# N32H49X register map
Vendor: Nsingtech Ltd.; File version: 1.0
Registers are 32-bit, read-write, reset 0x0 unless marked. A register's access mark holds for its fields unless they carry their own. Offsets are from the block's base; [hi:lo] are bit positions; {n}, {i} and the like mark numbered series; 'fields as' and 'values as' point back to an identical list.

## DVP — Digital video port
Base 0x40008400
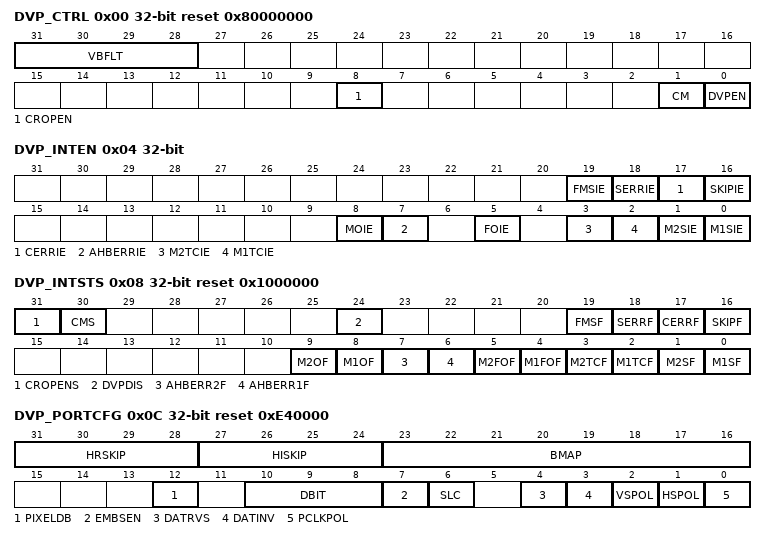
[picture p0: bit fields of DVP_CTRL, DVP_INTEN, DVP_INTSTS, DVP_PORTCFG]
0x00 DVP_CTRL reset 0x80000000
  [31:28] VBFLT, [8] CROPEN, [1] CM, [0] DVPEN
0x04 DVP_INTEN
  [19] FMSIE, [18] SERRIE, [17] CERRIE, [16] SKIPIE, [8] MOIE, [7] AHBERRIE, [5] FOIE, [3] M2TCIE, [2] M1TCIE, [1] M2SIE, [0] M1SIE
0x08 DVP_INTSTS reset 0x1000000
  [31] CROPENS ro, [30] CMS ro, [24] DVPDIS, [19] FMSF, [18] SERRF, [17] CERRF, [16] SKIPF, [9] M2OF, [8] M1OF, [7] AHBERR2F, [6] AHBERR1F, [5] M2FOF, [4] M1FOF, [3] M2TCF, [2] M1TCF, [1] M2SF, [0] M1SF
0x0C DVP_PORTCFG reset 0xE40000
  [31:28] HRSKIP, [27:24] HISKIP, [23:16] BMAP, [12] PIXELDB, [10:8] DBIT, [7] EMBSEN, [6] SLC, [4] DATRVS, [3] DATINV, [2] VSPOL, [1] HSPOL, [0] PCLKPOL
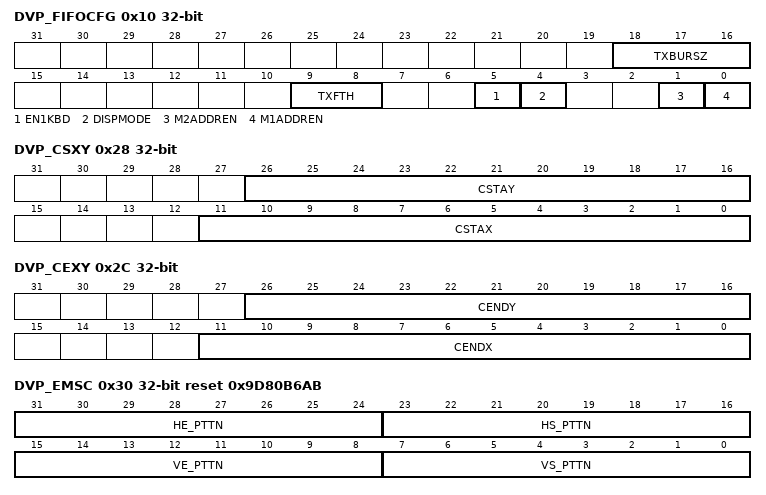
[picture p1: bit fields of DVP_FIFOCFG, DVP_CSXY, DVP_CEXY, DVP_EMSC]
0x10 DVP_FIFOCFG
  [18:16] TXBURSZ, [9:8] TXFTH, [5] EN1KBD, [4] DISPMODE, [1] M2ADDREN, [0] M1ADDREN
0x14 DVP_SMADDR1
  [31:0] MADDR
0x18 DVP_SMADDR2
  [31:0] MADDR
0x1C DVP_FBS
  [21:0] FMSIZE
0x20 DVP_FPBC1 ro
  [31:0] PIXLC
0x24 DVP_FPBC2 ro
  [31:0] PIXLC
0x28 DVP_CSXY
  [26:16] CSTAY, [11:0] CSTAX
0x2C DVP_CEXY
  [26:16] CENDY, [11:0] CENDX
0x30 DVP_EMSC reset 0x9D80B6AB
  [31:24] HE_PTTN, [23:16] HS_PTTN, [15:8] VE_PTTN, [7:0] VS_PTTN
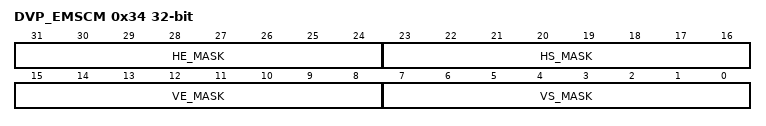
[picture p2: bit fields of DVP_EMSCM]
0x34 DVP_EMSCM
  [31:24] HE_MASK, [23:16] HS_MASK, [15:8] VE_MASK, [7:0] VS_MASK

## LPTIM1
Base 0x40006C00
Same registers: LPTIM2 0x40007000
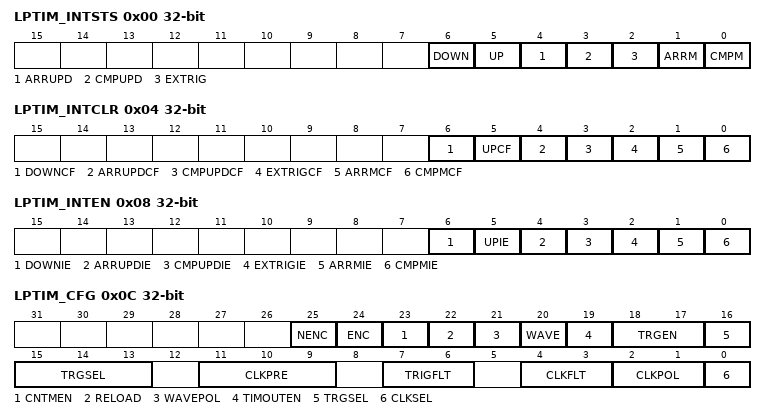
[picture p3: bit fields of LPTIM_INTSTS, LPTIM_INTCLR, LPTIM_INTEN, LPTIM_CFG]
0x00 LPTIM_INTSTS
  [6] DOWN, [5] UP, [4] ARRUPD, [3] CMPUPD, [2] EXTRIG, [1] ARRM, [0] CMPM
0x04 LPTIM_INTCLR
  [6] DOWNCF, [5] UPCF, [4] ARRUPDCF, [3] CMPUPDCF, [2] EXTRIGCF, [1] ARRMCF, [0] CMPMCF
0x08 LPTIM_INTEN
  [6] DOWNIE, [5] UPIE, [4] ARRUPDIE, [3] CMPUPDIE, [2] EXTRIGIE, [1] ARRMIE, [0] CMPMIE
0x0C LPTIM_CFG
  [25] NENC, [24] ENC, [23] CNTMEN, [22] RELOAD, [21] WAVEPOL, [20] WAVE, [19] TIMOUTEN, [18:17] TRGEN, [16:13] TRGSEL, [11:9] CLKPRE, [7:6] TRIGFLT, [4:3] CLKFLT, [2:1] CLKPOL, [0] CLKSEL
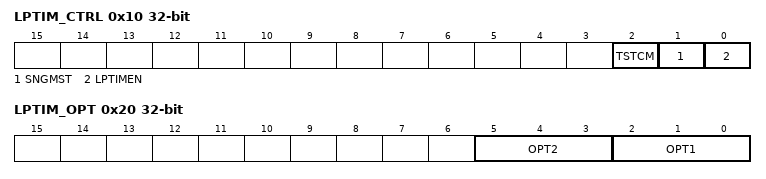
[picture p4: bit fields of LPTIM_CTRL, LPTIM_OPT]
0x10 LPTIM_CTRL
  [2] TSTCM, [1] SNGMST, [0] LPTIMEN
0x14 LPTIM_CMP
  [15:0] CMPVAL
0x18 LPTIM_ARR reset 0x1
  [15:0] ARRVAL
0x1C LPTIM_CNT
  [15:0] CNTVAL
0x20 LPTIM_OPT
  [5:3] OPT2, [2:0] OPT1

## USB_FS — Universal serial bus full-speed device interface
Base 0x40004800
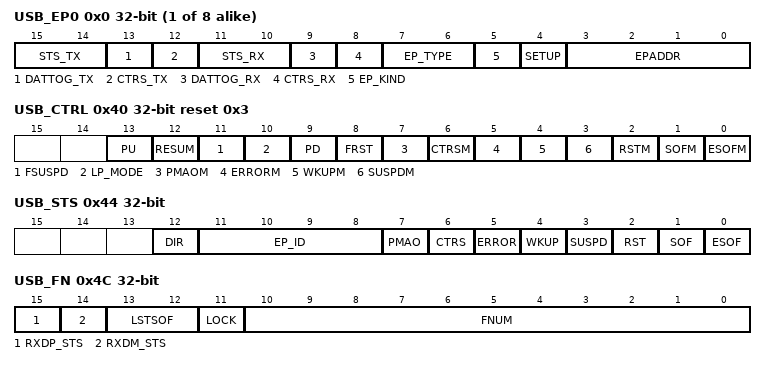
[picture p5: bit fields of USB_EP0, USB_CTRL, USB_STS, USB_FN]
{0x0+4i} USB_EP{i} (i=0..7)
  [15:14] STS_TX, [13] DATTOG_TX, [12] CTRS_TX, [11:10] STS_RX, [9] DATTOG_RX, [8] CTRS_RX, [7:6] EP_TYPE, [5] EP_KIND, [4] SETUP, [3:0] EPADDR
0x40 USB_CTRL reset 0x3 (reset mask 0xFF1F)
  [13] PU, [12] RESUM, [11] FSUSPD, [10] LP_MODE, [9] PD, [8] FRST, [7] PMAOM, [6] CTRSM, [5] ERRORM, [4] WKUPM, [3] SUSPDM, [2] RSTM, [1] SOFM, [0] ESOFM
0x44 USB_STS (reset mask 0xFF1F)
  [12] DIR, [11:8] EP_ID, [7] PMAO, [6] CTRS, [5] ERROR, [4] WKUP, [3] SUSPD, [2] RST, [1] SOF, [0] ESOF
0x48 USB_BUFTAB
  [15:3] BUFTAB
0x4C USB_FN
  [15] RXDP_STS, [14] RXDM_STS, [13:12] LSTSOF, [11] LOCK, [10:0] FNUM
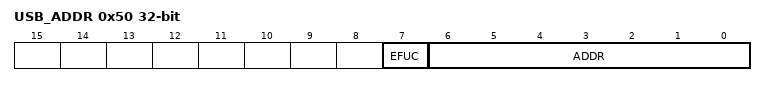
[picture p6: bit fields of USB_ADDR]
0x50 USB_ADDR (reset mask 0x7F)
  [7] EFUC, [6:0] ADDR

## USB_HS — USB high speed dual role
Base 0x40040000
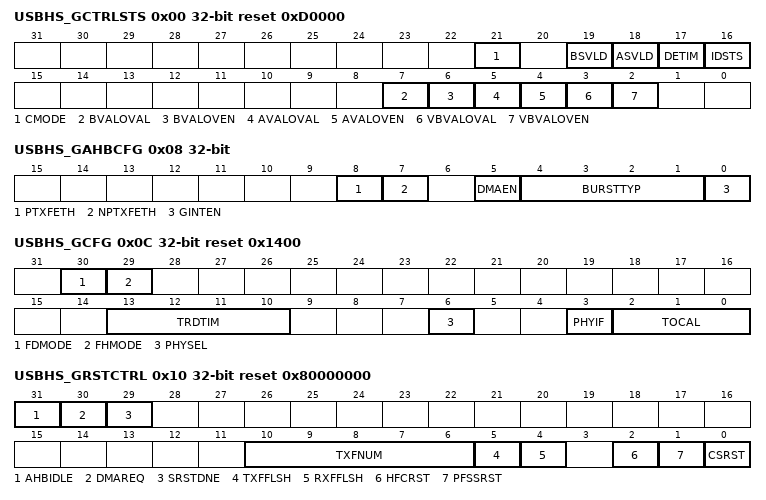
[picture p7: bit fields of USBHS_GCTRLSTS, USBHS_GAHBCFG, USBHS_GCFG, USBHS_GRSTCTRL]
0x00 USBHS_GCTRLSTS reset 0xD0000 — USBHS global control and status register
  [21] CMODE ro, [19] BSVLD ro, [18] ASVLD ro, [17] DETIM ro, [16] IDSTS ro, [7] BVALOVAL, [6] BVALOVEN, [5] AVALOVAL, [4] AVALOVEN, [3] VBVALOVAL, [2] VBVALOVEN
0x08 USBHS_GAHBCFG
  [8] PTXFETH, [7] NPTXFETH, [5] DMAEN, [4:1] BURSTTYP, [0] GINTEN
0x0C USBHS_GCFG reset 0x1400
  [30] FDMODE, [29] FHMODE, [13:10] TRDTIM, [6] PHYSEL, [3] PHYIF wo, [2:0] TOCAL
0x10 USBHS_GRSTCTRL reset 0x80000000
  [31] AHBIDLE ro, [30] DMAREQ ro, [29] SRSTDNE ro, [10:6] TXFNUM, [5] TXFFLSH, [4] RXFFLSH, [2] HFCRST, [1] PFSSRST, [0] CSRST
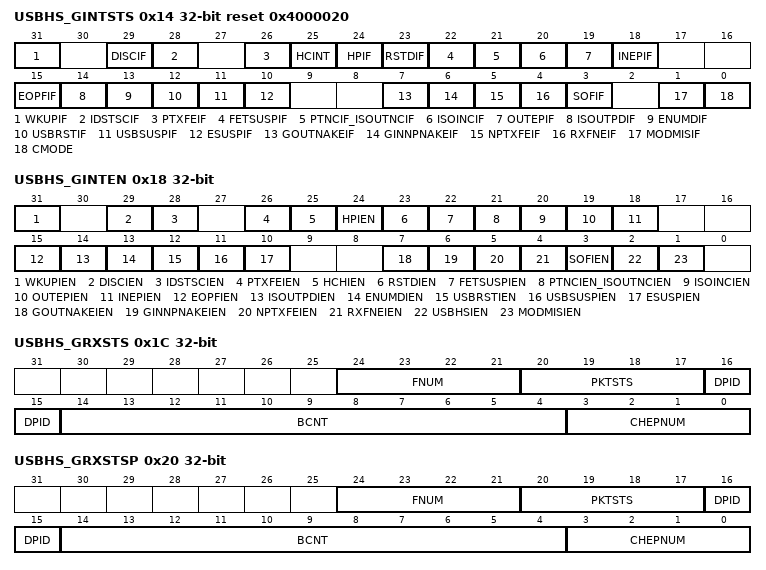
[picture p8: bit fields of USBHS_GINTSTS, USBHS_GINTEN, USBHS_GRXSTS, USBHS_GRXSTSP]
0x14 USBHS_GINTSTS reset 0x4000020
  [31] WKUPIF
  [29] DISCIF
  [28] IDSTSCIF
  [26] PTXFEIF ro
  [25] HCINT ro — Host channels interrupt
  [24] HPIF ro
  [23] RSTDIF
  [22] FETSUSPIF
  [21] PTNCIF_ISOUTNCIF
  [20] ISOINCIF
  [19] OUTEPIF ro
  [18] INEPIF ro
  [15] EOPFIF
  [14] ISOUTPDIF
  [13] ENUMDIF
  [12] USBRSTIF
  [11] USBSUSPIF
  [10] ESUSPIF
  [7] GOUTNAKEIF ro
  [6] GINNPNAKEIF ro
  [5] NPTXFEIF ro
  [4] RXFNEIF ro
  [3] SOFIF
  [1] MODMISIF
  [0] CMODE ro
0x18 USBHS_GINTEN
  [31] WKUPIEN, [29] DISCIEN, [28] IDSTSCIEN, [26] PTXFEIEN, [25] HCHIEN, [24] HPIEN, [23] RSTDIEN, [22] FETSUSPIEN, [21] PTNCIEN_ISOUTNCIEN, [20] ISOINCIEN, [19] OUTEPIEN, [18] INEPIEN, [15] EOPFIEN, [14] ISOUTPDIEN, [13] ENUMDIEN, [12] USBRSTIEN, [11] USBSUSPIEN, [10] ESUSPIEN, [7] GOUTNAKEIEN, [6] GINNPNAKEIEN, [5] NPTXFEIEN, [4] RXFNEIEN, [3] SOFIEN, [2] USBHSIEN, [1] MODMISIEN
0x1C USBHS_GRXSTS ro
  [24:21] FNUM, [20:17] PKTSTS, [16:15] DPID, [14:4] BCNT, [3:0] CHEPNUM
0x20 USBHS_GRXSTSP ro
  fields as USBHS_GRXSTS
0x24 USBHS_GRXFSIZ reset 0x200
  [10:0] RXFDEP
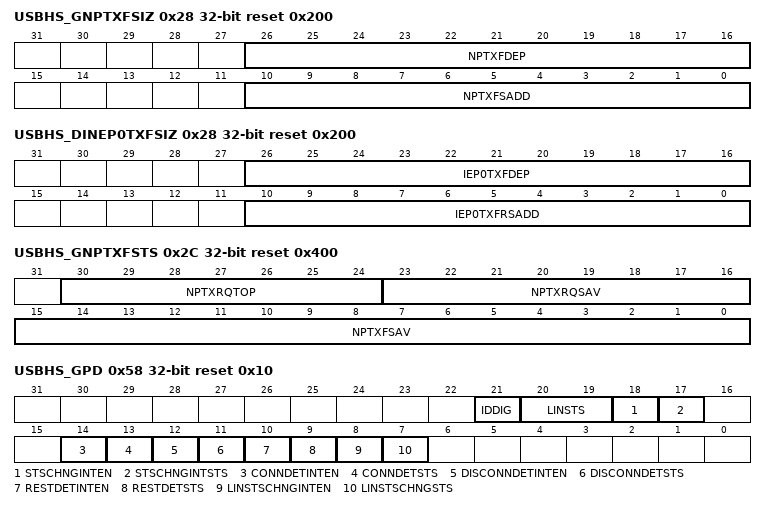
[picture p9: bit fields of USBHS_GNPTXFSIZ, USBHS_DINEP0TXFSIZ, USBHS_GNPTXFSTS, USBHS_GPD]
0x28 USBHS_GNPTXFSIZ reset 0x200
  [26:16] NPTXFDEP
  [10:0] NPTXFSADD — NNPTXFSADD
0x28 USBHS_DINEP0TXFSIZ reset 0x200 (alternate view of USBHS_GNPTXFSIZ) — EUSBHS_DINEP0TXFSIZ
  [26:16] IEP0TXFDEP, [10:0] IEP0TXFRSADD
0x2C USBHS_GNPTXFSTS ro reset 0x400
  [30:24] NPTXRQTOP, [23:16] NPTXRQSAV, [15:0] NPTXFSAV
0x3C USBHS_CID reset 0x3608
0x58 USBHS_GPD reset 0x10
  [21] IDDIG, [20:19] LINSTS, [18] STSCHNGINTEN, [17] STSCHNGINTSTS, [14] CONNDETINTEN, [13] CONNDETSTS, [12] DISCONNDETINTEN, [11] DISCONNDETSTS, [10] RESTDETINTEN, [9] RESTDETSTS, [8] LINSTSCHNGINTEN, [7] LINSTSCHNGSTS
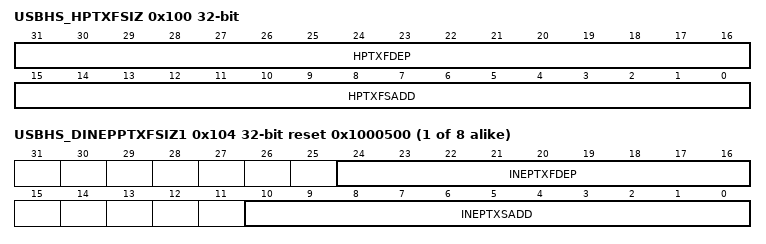
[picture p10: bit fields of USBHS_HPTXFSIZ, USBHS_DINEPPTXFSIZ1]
0x100 USBHS_HPTXFSIZ
  [31:16] HPTXFDEP, [15:0] HPTXFSADD
{0x100+4i} USBHS_DINEPPTXFSIZ{i} reset 0x1000500 (i=1..8)
  [24:16] INEPTXFDEP, [10:0] INEPTXSADD
